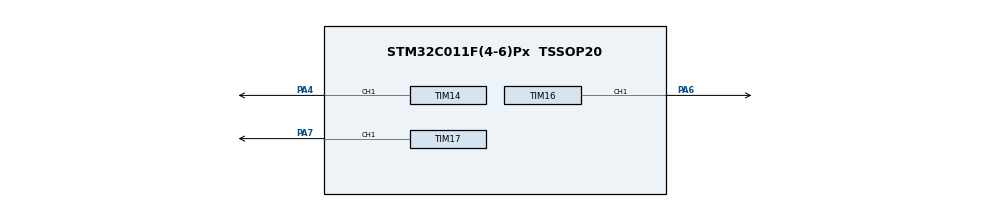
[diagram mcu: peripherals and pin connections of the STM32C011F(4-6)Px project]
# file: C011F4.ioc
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Mcu.Family=STM32C0
Mcu.Name=STM32C011F(4-6)Px
Mcu.Package=TSSOP20
PA13.Mode=Serial_Wire
PA13.Signal=DEBUG_SWDIO
PA14-BOOT0.Mode=Serial_Wire
PA14-BOOT0.Signal=DEBUG_SWCLK
PA4.Signal=S_TIM14_CH1
PA6.Signal=S_TIM16_CH1
PA7.Signal=S_TIM17_CH1
ProjectManager.HeapSize=0x200
ProjectManager.StackSize=0x400
ProjectManager.TargetToolchain=STM32CubeIDE
RCC.ADCFreq_Value=12000000
RCC.AHBFreq_Value=12000000
RCC.CortexFreq_Value=12000000
RCC.EXTERNAL_CLOCK_VALUE=12288000
RCC.HCLKFreq_Value=12000000
RCC.HSE_VALUE=32000000
RCC.HSI_VALUE=48000000
RCC.LSE_VALUE=32768
RCC.SYSCLKFreq_VALUE=12000000
SH.S_TIM14_CH1.0=TIM14_CH1,PWM Generation1 CH1
SH.S_TIM16_CH1.0=TIM16_CH1,Output Compare1 CH1
SH.S_TIM17_CH1.0=TIM17_CH1,Output Compare1 CH1
TIM14.Channel=TIM_CHANNEL_1
TIM14.Period=5-1
TIM14.Prescaler=1-1
TIM16.Channel=TIM_CHANNEL_1
TIM16.Period=5-1
TIM17.Channel=TIM_CHANNEL_1
TIM17.Period=5-1
TIM17.Prescaler=1-1
VP_TIM14_VS_ClockSourceINT.Mode=Enable_Timer
VP_TIM16_VS_ClockSourceINT.Mode=Enable_Timer
VP_TIM17_VS_ClockSourceINT.Mode=Enable_Timer
board=custom

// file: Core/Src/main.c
/* USER CODE BEGIN Header */
/**
  ******************************************************************************
  * @file           : main.c
  * @brief          : Main program body
  ******************************************************************************
  * @attention
  *
  * Copyright (c) 2024 STMicroelectronics.
  * All rights reserved.
  *
  * This software is licensed under terms that can be found in the LICENSE file
  * in the root directory of this software component.
  * If no LICENSE file comes with this software, it is provided AS-IS.
  *
  ******************************************************************************
  */
/* USER CODE END Header */
#include "main.h"

TIM_HandleTypeDef htim14;
TIM_HandleTypeDef htim16;
TIM_HandleTypeDef htim17;

void SystemClock_Config(void);
static void MX_GPIO_Init(void);
static void MX_TIM14_Init(void);
static void MX_TIM16_Init(void);
static void MX_TIM17_Init(void);

int main(void)
{

  /* MCU Configuration--------------------------------------------------------*/

  /* Reset of all peripherals, Initializes the Flash interface and the Systick. */
  HAL_Init();

  /* Configure the system clock */
  SystemClock_Config();

  /* Initialize all configured peripherals */
  MX_GPIO_Init();
  MX_TIM14_Init();
  MX_TIM16_Init();
  MX_TIM17_Init();

  /* Infinite loop */
  while (1)
  {

    /* USER CODE BEGIN 3 */
//	__HAL_TIM_SET_COMPARE(&htim14, TIM_CHANNEL_1, 1);
//	__HAL_TIM_SET_COMPARE(&htim16, TIM_CHANNEL_1, 0);
//	__HAL_TIM_SET_COMPARE(&htim17, TIM_CHANNEL_1, 0);
//	HAL_Delay(10);
	__HAL_TIM_SET_COMPARE(&htim14, TIM_CHANNEL_1, 0);
	__HAL_TIM_SET_COMPARE(&htim16, TIM_CHANNEL_1, 0);
	__HAL_TIM_SET_COMPARE(&htim17, TIM_CHANNEL_1, 0);
	HAL_Delay(10);
	__HAL_TIM_SET_COMPARE(&htim14, TIM_CHANNEL_1, 0);
	__HAL_TIM_SET_COMPARE(&htim16, TIM_CHANNEL_1, 0);
	__HAL_TIM_SET_COMPARE(&htim17, TIM_CHANNEL_1, 0);
	HAL_Delay(10);
  }
  /* USER CODE END 3 */
}

void SystemClock_Config(void)
{
  RCC_OscInitTypeDef RCC_OscInitStruct = {0};
  RCC_ClkInitTypeDef RCC_ClkInitStruct = {0};

  /** Initializes the RCC Oscillators according to the specified parameters
  * in the RCC_OscInitTypeDef structure.
  */
  RCC_OscInitStruct.OscillatorType = RCC_OSCILLATORTYPE_HSI;
  RCC_OscInitStruct.HSIState = RCC_HSI_ON;
  RCC_OscInitStruct.HSIDiv = RCC_HSI_DIV4;
  RCC_OscInitStruct.HSICalibrationValue = RCC_HSICALIBRATION_DEFAULT;
  if (HAL_RCC_OscConfig(&RCC_OscInitStruct) != HAL_OK)
  {
    Error_Handler();
  }

  /** Initializes the CPU, AHB and APB buses clocks
  */
  RCC_ClkInitStruct.ClockType = RCC_CLOCKTYPE_HCLK|RCC_CLOCKTYPE_SYSCLK
                              |RCC_CLOCKTYPE_PCLK1;
  RCC_ClkInitStruct.SYSCLKSource = RCC_SYSCLKSOURCE_HSI;
  RCC_ClkInitStruct.SYSCLKDivider = RCC_SYSCLK_DIV1;
  RCC_ClkInitStruct.AHBCLKDivider = RCC_HCLK_DIV1;
  RCC_ClkInitStruct.APB1CLKDivider = RCC_APB1_DIV1;

  if (HAL_RCC_ClockConfig(&RCC_ClkInitStruct, FLASH_LATENCY_0) != HAL_OK)
  {
    Error_Handler();
  }
}

static void MX_TIM14_Init(void)
{

  TIM_OC_InitTypeDef sConfigOC = {0};

  htim14.Instance = TIM14;
  htim14.Init.Prescaler = 1-1;
  htim14.Init.CounterMode = TIM_COUNTERMODE_UP;
  htim14.Init.Period = 5-1;
  htim14.Init.ClockDivision = TIM_CLOCKDIVISION_DIV1;
  htim14.Init.AutoReloadPreload = TIM_AUTORELOAD_PRELOAD_DISABLE;
  if (HAL_TIM_Base_Init(&htim14) != HAL_OK)
  {
    Error_Handler();
  }
  if (HAL_TIM_PWM_Init(&htim14) != HAL_OK)
  {
    Error_Handler();
  }
  sConfigOC.OCMode = TIM_OCMODE_PWM1;
  sConfigOC.Pulse = 0;
  sConfigOC.OCPolarity = TIM_OCPOLARITY_HIGH;
  sConfigOC.OCFastMode = TIM_OCFAST_DISABLE;
  if (HAL_TIM_PWM_ConfigChannel(&htim14, &sConfigOC, TIM_CHANNEL_1) != HAL_OK)
  {
    Error_Handler();
  }
  HAL_TIM_MspPostInit(&htim14);

}

static void MX_TIM16_Init(void)
{

  TIM_OC_InitTypeDef sConfigOC = {0};
  TIM_BreakDeadTimeConfigTypeDef sBreakDeadTimeConfig = {0};

  htim16.Instance = TIM16;
  htim16.Init.Prescaler = 0;
  htim16.Init.CounterMode = TIM_COUNTERMODE_UP;
  htim16.Init.Period = 5-1;
  htim16.Init.ClockDivision = TIM_CLOCKDIVISION_DIV1;
  htim16.Init.RepetitionCounter = 0;
  htim16.Init.AutoReloadPreload = TIM_AUTORELOAD_PRELOAD_DISABLE;
  if (HAL_TIM_Base_Init(&htim16) != HAL_OK)
  {
    Error_Handler();
  }
  if (HAL_TIM_OC_Init(&htim16) != HAL_OK)
  {
    Error_Handler();
  }
  sConfigOC.OCMode = TIM_OCMODE_TIMING;
  sConfigOC.Pulse = 0;
  sConfigOC.OCPolarity = TIM_OCPOLARITY_HIGH;
  sConfigOC.OCNPolarity = TIM_OCNPOLARITY_HIGH;
  sConfigOC.OCFastMode = TIM_OCFAST_DISABLE;
  sConfigOC.OCIdleState = TIM_OCIDLESTATE_RESET;
  sConfigOC.OCNIdleState = TIM_OCNIDLESTATE_RESET;
  if (HAL_TIM_OC_ConfigChannel(&htim16, &sConfigOC, TIM_CHANNEL_1) != HAL_OK)
  {
    Error_Handler();
  }
  sBreakDeadTimeConfig.OffStateRunMode = TIM_OSSR_DISABLE;
  sBreakDeadTimeConfig.OffStateIDLEMode = TIM_OSSI_DISABLE;
  sBreakDeadTimeConfig.LockLevel = TIM_LOCKLEVEL_OFF;
  sBreakDeadTimeConfig.DeadTime = 0;
  sBreakDeadTimeConfig.BreakState = TIM_BREAK_DISABLE;
  sBreakDeadTimeConfig.BreakPolarity = TIM_BREAKPOLARITY_HIGH;
  sBreakDeadTimeConfig.BreakFilter = 0;
  sBreakDeadTimeConfig.AutomaticOutput = TIM_AUTOMATICOUTPUT_DISABLE;
  if (HAL_TIMEx_ConfigBreakDeadTime(&htim16, &sBreakDeadTimeConfig) != HAL_OK)
  {
    Error_Handler();
  }
  HAL_TIM_MspPostInit(&htim16);

}

static void MX_TIM17_Init(void)
{

  TIM_OC_InitTypeDef sConfigOC = {0};
  TIM_BreakDeadTimeConfigTypeDef sBreakDeadTimeConfig = {0};

  htim17.Instance = TIM17;
  htim17.Init.Prescaler = 1-1;
  htim17.Init.CounterMode = TIM_COUNTERMODE_UP;
  htim17.Init.Period = 5-1;
  htim17.Init.ClockDivision = TIM_CLOCKDIVISION_DIV1;
  htim17.Init.RepetitionCounter = 0;
  htim17.Init.AutoReloadPreload = TIM_AUTORELOAD_PRELOAD_DISABLE;
  if (HAL_TIM_Base_Init(&htim17) != HAL_OK)
  {
    Error_Handler();
  }
  if (HAL_TIM_OC_Init(&htim17) != HAL_OK)
  {
    Error_Handler();
  }
  sConfigOC.OCMode = TIM_OCMODE_TIMING;
  sConfigOC.Pulse = 0;
  sConfigOC.OCPolarity = TIM_OCPOLARITY_HIGH;
  sConfigOC.OCNPolarity = TIM_OCNPOLARITY_HIGH;
  sConfigOC.OCFastMode = TIM_OCFAST_DISABLE;
  sConfigOC.OCIdleState = TIM_OCIDLESTATE_RESET;
  sConfigOC.OCNIdleState = TIM_OCNIDLESTATE_RESET;
  if (HAL_TIM_OC_ConfigChannel(&htim17, &sConfigOC, TIM_CHANNEL_1) != HAL_OK)
  {
    Error_Handler();
  }
  sBreakDeadTimeConfig.OffStateRunMode = TIM_OSSR_DISABLE;
  sBreakDeadTimeConfig.OffStateIDLEMode = TIM_OSSI_DISABLE;
  sBreakDeadTimeConfig.LockLevel = TIM_LOCKLEVEL_OFF;
  sBreakDeadTimeConfig.DeadTime = 0;
  sBreakDeadTimeConfig.BreakState = TIM_BREAK_DISABLE;
  sBreakDeadTimeConfig.BreakPolarity = TIM_BREAKPOLARITY_HIGH;
  sBreakDeadTimeConfig.BreakFilter = 0;
  sBreakDeadTimeConfig.AutomaticOutput = TIM_AUTOMATICOUTPUT_DISABLE;
  if (HAL_TIMEx_ConfigBreakDeadTime(&htim17, &sBreakDeadTimeConfig) != HAL_OK)
  {
    Error_Handler();
  }
  HAL_TIM_MspPostInit(&htim17);

}

static void MX_GPIO_Init(void)
{

  /* GPIO Ports Clock Enable */
  __HAL_RCC_GPIOA_CLK_ENABLE();

}

void Error_Handler(void)
{
  __disable_irq();
  while (1)
  {
  }
}
